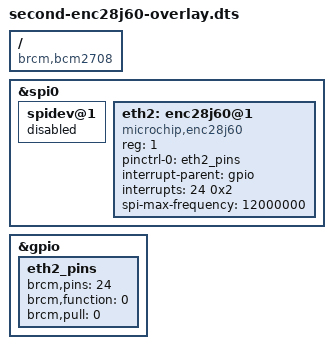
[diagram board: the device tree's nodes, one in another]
// Overlay for a seconf Microchip ENC28J60 Ethernet Controller
/dts-v1/;
/plugin/;

/ {
	compatible = "brcm,bcm2708";

	fragment@0 {
		target = <&spi0>;
		__overlay__ {
			/* needed to avoid dtc warning */
			#address-cells = <1>;
			#size-cells = <0>;

			status = "okay";

			spidev@1{
				status = "disabled";
			};

			eth2: enc28j60@1{
				compatible = "microchip,enc28j60";
				reg = <1>; /* CE1 */
				pinctrl-names = "default";
				pinctrl-0 = <&eth2_pins>;
				interrupt-parent = <&gpio>;
				interrupts = <24 0x2>; /* falling edge */
				spi-max-frequency = <12000000>;
				status = "okay";
			};
		};
	};

	fragment@1 {
		target = <&gpio>;
		__overlay__ {
			eth2_pins: eth2_pins {
				brcm,pins = <24>;
				brcm,function = <0>; /* in */
				brcm,pull = <0>; /* none */
			};
		};
	};

	__overrides__ {
		int_pin = <&eth2>, "interrupts:0",
		          <&eth2_pins>, "brcm,pins:0";
		speed   = <&eth2>, "spi-max-frequency:0";
	};
};
